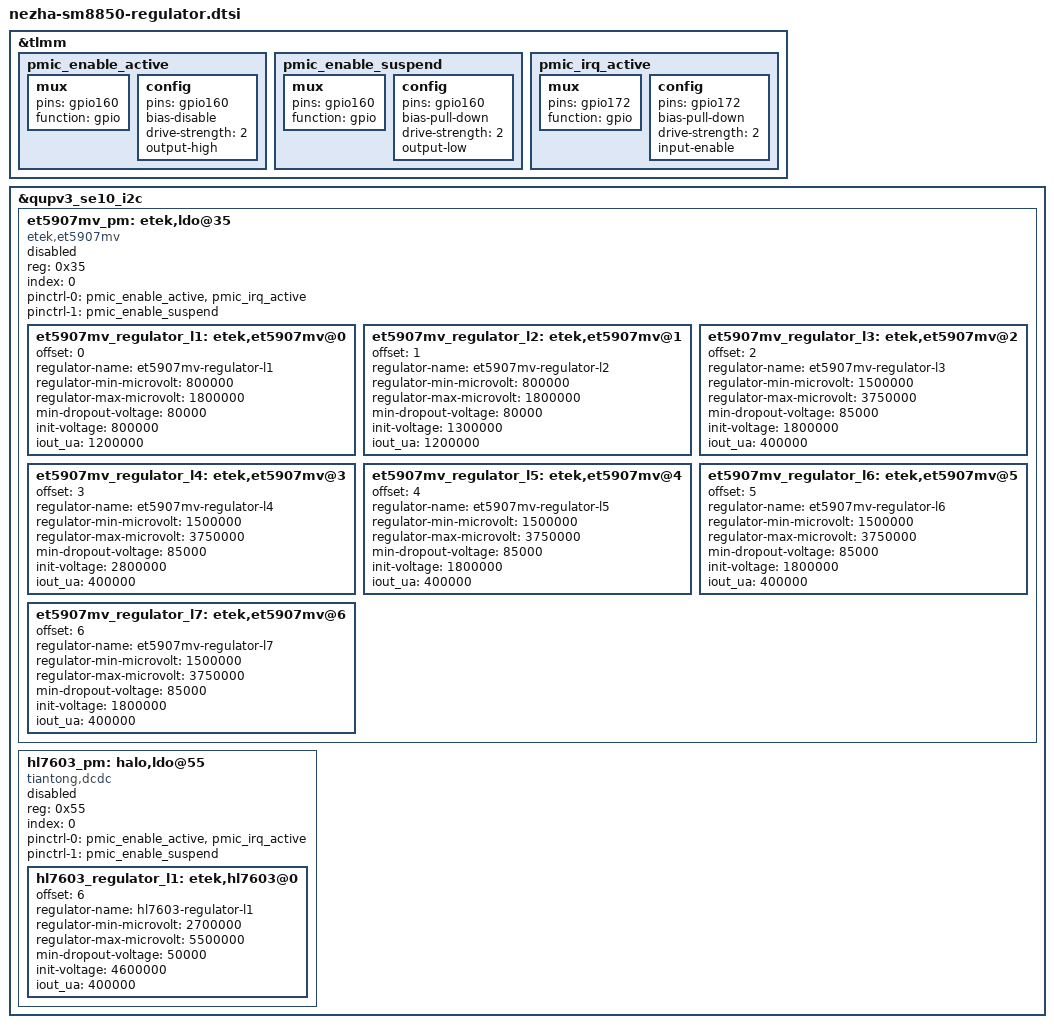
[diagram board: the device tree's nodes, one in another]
// SPDX-License-Identifier: GPL-2.0-only

&tlmm {
	pmic_enable_active: pmic_enable_active {
		mux {
			pins = "gpio160";
			function = "gpio";
		};

		config {
			pins = "gpio160";
			bias-disable;
			drive-strength = <2>;
			output-high;
		};
	};

	pmic_enable_suspend: pmic_enable_suspend {
		mux {
			pins = "gpio160";
			function = "gpio";
		};

		config {
			pins = "gpio160";
			bias-pull-down;
			drive-strength = <2>;
			output-low;
		};
	};

	pmic_irq_active: pmic_irq_active {
		mux {
			pins = "gpio172";
			function = "gpio";
		};

		config {
			pins = "gpio172";
			bias-pull-down;
			drive-strength = <2>;
			input-enable;
		};
	};
};

&qupv3_se10_i2c {
	#address-cells = <1>;
	#size-cells = <0>;
	status = "okay";

	et5907mv_pm: etek,ldo@35 {
		compatible = "etek,et5907mv";
		status = "disabled";
		reg = <0x35>;
		index = <0>;
		pinctrl-names = "et5907mv_enable", "et5907mv_disable";
		pinctrl-0 = <&pmic_enable_active &pmic_irq_active>;
		pinctrl-1 = <&pmic_enable_suspend>;

		et5907mv_regulator_l1: etek,et5907mv@0 {
			offset = /bits/ 16 <0>;
			regulator-name = "et5907mv-regulator-l1";
			regulator-min-microvolt = <800000>;
			regulator-max-microvolt = <1800000>;
			min-dropout-voltage = <80000>;
			init-voltage = <800000>;
			iout_ua = <1200000>;
		};

		et5907mv_regulator_l2: etek,et5907mv@1 {
			offset = /bits/ 16 <1>;
			regulator-name = "et5907mv-regulator-l2";
			regulator-min-microvolt = <800000>;
			regulator-max-microvolt = <1800000>;
			min-dropout-voltage = <80000>;
			init-voltage = <1300000>;
			iout_ua = <1200000>;
		};

		et5907mv_regulator_l3: etek,et5907mv@2 {
			offset = /bits/ 16 <2>;
			regulator-name = "et5907mv-regulator-l3";
			regulator-min-microvolt = <1500000>;
			regulator-max-microvolt = <3750000>;
			min-dropout-voltage = <85000>;
			init-voltage = <1800000>;
			iout_ua = <400000>;
		};

		et5907mv_regulator_l4: etek,et5907mv@3 {
			offset = /bits/ 16 <3>;
			regulator-name = "et5907mv-regulator-l4";
			regulator-min-microvolt = <1500000>;
			regulator-max-microvolt = <3750000>;
			min-dropout-voltage = <85000>;
			init-voltage = <2800000>;
			iout_ua = <400000>;
		};

		et5907mv_regulator_l5: etek,et5907mv@4 {
			offset = /bits/ 16 <4>;
			regulator-name = "et5907mv-regulator-l5";
			regulator-min-microvolt = <1500000>;
			regulator-max-microvolt = <3750000>;
			min-dropout-voltage = <85000>;
			init-voltage = <1800000>;
			iout_ua = <400000>;
		};

		et5907mv_regulator_l6: etek,et5907mv@5 {
			offset = /bits/ 16 <5>;
			regulator-name = "et5907mv-regulator-l6";
			regulator-min-microvolt = <1500000>;
			regulator-max-microvolt = <3750000>;
			min-dropout-voltage = <85000>;
			init-voltage = <1800000>;
			iout_ua = <400000>;
		};

		et5907mv_regulator_l7: etek,et5907mv@6 {
			offset = /bits/ 16 <6>;
			regulator-name = "et5907mv-regulator-l7";
			regulator-min-microvolt = <1500000>;
			regulator-max-microvolt = <3750000>;
			min-dropout-voltage = <85000>;
			init-voltage = <1800000>;
			iout_ua = <400000>;
		};
	};

	hl7603_pm: halo,ldo@55 {
		compatible = "tiantong,dcdc";
		status = "disabled";
		reg = <0x55>;
		index = <0>;
		pinctrl-names = "hl7603_enable", "hl7603_disable";
		pinctrl-0 = <&pmic_enable_active &pmic_irq_active>;
		pinctrl-1 = <&pmic_enable_suspend>;

		hl7603_regulator_l1: etek,hl7603@0 {
			offset = /bits/ 16 <6>;
			regulator-name = "hl7603-regulator-l1";
			regulator-min-microvolt = <2700000>;
			regulator-max-microvolt = <5500000>;
			min-dropout-voltage = <50000>;
			init-voltage = <4600000>;
			iout_ua = <400000>;
		};
	};
};
